# FDIF register map
Vendor: Texas Instruments
Peripheral module from a debugger description file (folder omap4460).
Registers are 32-bit, read-only, no defined reset value unless marked. A register's access mark holds for its fields unless they carry their own. Offsets are as the file gives them; lines under a group give offsets from that group; [hi:lo] are bit positions; {n}, {i} and the like mark numbered series; 'fields as' and 'values as' point back to an identical list; <NAME> marks a mode.

## FDIF
0x00 FDIF_REVISION — IP Revision Identifier (X.Y.R) Used by software to track features, bugs, and compatibility
  [31:0] REVISION — IP Revision number
0x04 FDIF_HWINFO reset 0xF — Information about the IP module's hardware configuration, that is, typically the module's HDL generics (if any). Actual field format and encoding is up to the module's designer to decide.
  [3:0] FDIF_TAGS — Hardware design value. This bit field reflects the value of the FDIF_TAG generic parameter. 0x0: 1 tag supported 0x1: 2 tags supported [...] 0xF: 16 tags supported
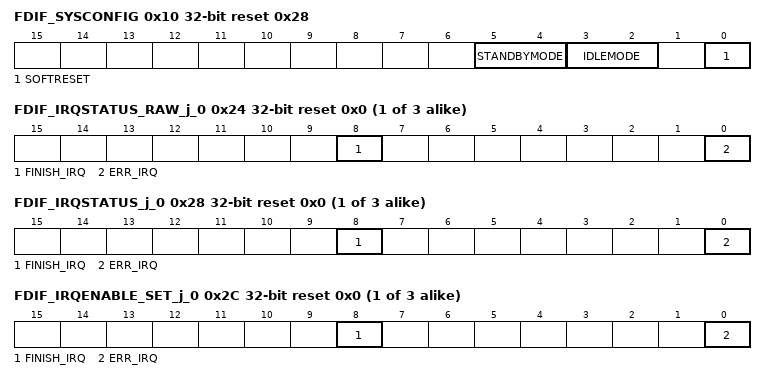
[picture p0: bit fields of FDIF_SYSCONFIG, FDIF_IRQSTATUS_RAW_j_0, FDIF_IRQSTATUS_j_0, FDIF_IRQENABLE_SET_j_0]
0x10 FDIF_SYSCONFIG access per field reset 0x28 — Clock management configuration
  [5:4] STANDBYMODE rw — Configuration of the local initiator state management mode. By definition, initiator may generate read/write transaction as long as it is out of STANDBY state.
    0=Force-standby mode: local initiator is unconditionally placed in standby state. Backup mode, for debug only.; 1=No-standby mode: local initiator is unconditionally placed out of standby state. Backup mode, for debug only.; 2=Smart-standby mode: local initiator standby status depends on local conditions, that is, the module's functional requirement from the initiator. IP module shall not generate (initiator-related) wake-up events.
  [3:2] IDLEMODE rw — Configuration of the local target state management mode. By definition, target can handle read/write transaction as long as it is out of IDLE state.
    0=Force-idle mode: local target's idle state follows (acknowledges) the system's idle requests unconditionally, that is, regardless of the IP module's internal requirements. Backup mode, for debug only.; 1=No-idle mode: local target never enters idle state. Backup mode, for debug only.; 2=Smart-idle mode: local target's idle state eventually follows (acknowledges) the system's idle requests, depending on the IP module's internal requirements. IP module shall not generate (IRQ- or DMA-request-related) wake-up events.
  [0] SOFTRESET rw — Software reset.
    0=SOFTRESET_0_r (Reset done, no pending action); 0=SOFTRESET_0_w (No action); 1=SOFTRESET_1_w (Initiate software reset); 1=SOFTRESET_1_r (Reset (software or other) ongoing)
{0x24+0x10*i} FDIF_IRQSTATUS_RAW_j_{i} access not given reset 0x0 (i=0..2) — Per-event raw interrupt status vector, line #n. Raw status is set even if event is not enabled. Write 1 to set the (raw) status, mostly for debug.
  [8] FINISH_IRQ — Face detection processing done. (access RW W1toSet)
    0=FINISH_IRQ_0_w (No action); 0=FINISH_IRQ_0_r (No event pending); 1=FINISH_IRQ_1_r (Event pending); 1=FINISH_IRQ_1_w (Set event (debug))
  [0] ERR_IRQ — Error received by the L3 port. (access RW W1toSet)
    0=ERR_IRQ_0_w (No action); 0=ERR_IRQ_0_r (No event pending); 1=ERR_IRQ_1_r (Event pending); 1=ERR_IRQ_1_w (Set event (debug))
{0x28+0x10*i} FDIF_IRQSTATUS_j_{i} access not given reset 0x0 (i=0..2) — Per-event 'enabled' interrupt status vector, line #n. Enabled status is not set unless event is enabled. Write 1 to clear the status after interrupt has been serviced (raw status gets cleared, that is, even if not enabled).
  [8] FINISH_IRQ — Face detection processing done. (access RW W1toClr)
    0=FINISH_IRQ_0_w (No action); 0=FINISH_IRQ_0_r (No (enabled) event pending); 1=FINISH_IRQ_1_r (Event pending); 1=FINISH_IRQ_1_w (Clear (raw) event)
  [0] ERR_IRQ — Error received by the L3 port. (access RW W1toClr)
    0=ERR_IRQ_0_w (No action); 0=ERR_IRQ_0_r (No (enabled) event pending); 1=ERR_IRQ_1_r (Event pending); 1=ERR_IRQ_1_w (Clear (raw) event)
{0x2C+0x10*i} FDIF_IRQENABLE_SET_j_{i} access not given reset 0x0 (i=0..2) — Per-event interrupt enable bit vector, line #n. Write 1 to set (enable interrupt). Readout equal to corresponding _CLR register.
  [8] FINISH_IRQ — Face detection processing done. (access RW W1toSet)
    0=FINISH_IRQ_0_w (No action); 0=FINISH_IRQ_0_r (Interrupt disabled (masked)); 1=FINISH_IRQ_1_r (Interrupt enabled); 1=FINISH_IRQ_1_w (Enable interrupt)
  [0] ERR_IRQ — Error received by the L3 port. (access RW W1toSet)
    0=ERR_IRQ_0_w (No action); 0=ERR_IRQ_0_r (Interrupt disabled (masked)); 1=ERR_IRQ_1_r (Interrupt enabled); 1=ERR_IRQ_1_w (Enable interrupt)
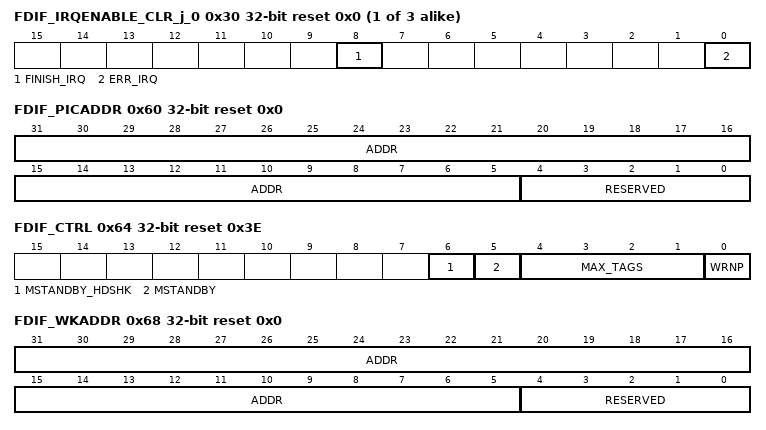
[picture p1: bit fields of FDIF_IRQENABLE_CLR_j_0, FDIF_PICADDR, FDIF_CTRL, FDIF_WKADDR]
{0x30+0x10*i} FDIF_IRQENABLE_CLR_j_{i} access not given reset 0x0 (i=0..2) — Per-event interrupt enable bit vector, line #n. Write 1 to clear (disable interrupt). Readout equal to corresponding _SET register.
  [8] FINISH_IRQ — Face detection processing done. (access RW W1toClr)
    0=FINISH_IRQ_0_w (No action); 0=FINISH_IRQ_0_r (Interrupt disabled (masked)); 1=FINISH_IRQ_1_r (Interrupt enabled); 1=FINISH_IRQ_1_w (Disable interrupt)
  [0] ERR_IRQ — Error received by the L3 port. (access RW W1toClr)
    0=ERR_IRQ_0_w (No action); 0=ERR_IRQ_0_r (Interrupt disabled (masked)); 1=ERR_IRQ_1_r (Interrupt enabled); 1=ERR_IRQ_1_w (Disable interrupt)
0x60 FDIF_PICADDR access per field reset 0x0 — Picture data store address
  [31:5] ADDR rw — Picture data store address. The 5 least significant bits are forced to 0.
  [4:0] RESERVED ro — Read returns 0.
0x64 FDIF_CTRL access per field reset 0x3E
  [6] MSTANDBY_HDSHK ro — MStandby / Wait power management handshaking status bit The power management framework of the FDIF module is based on the handshaking of the MSTANDBY and WAIT signals. When going from a idle to normal power management transition, the software polls for FDIF_CTRL.MSTANDBY_HDSHK = 1 before starting the face detection processing.
    0=MSTANDBY_HDSHK_0_r (Handshaking not completed. Do not initiate traffic on L3.); 1=MSTANDBY_HDSHK_1_r (Handshaking completed. Can safely use the FDIF module.)
  [5] MSTANDBY rw — MStandby signal generation. This bit shall be set to initiate a power management transition from NORMAL to IDLE or IDLE to NORMAL.
    0=Write: Clear MStandby signal. One polls.MSTANDBY_HDSHK = 1 after writing this bit to ensure that the power management handshaking is completed.; 1=Write: Asserts MStandby signal
  [4:1] MAX_TAGS rw — Max interconnect tags. This bit field sets the maximum number of interconnect tags that the module shall use. This number is programmable between 1 (MAX_TAGS = 0) and FDIF_TAGS (MAX_TAGS = FDIF_TAGS - 1). The value of MAX_TAGS is reflected in the FIDIF_HWINFO register setting. This register setting is expected to have impact on performance. It shall be set once at initialization. Higher value will give more bandwidth to the initiator. Lower value will give less bandwidth to the initiator. This value shall be set as low as possible such that other system initiators are not penalized.
  [0] WRNP rw — L3 port non-posted write control. Dynamic usage of this feature is not supported. This bit shall be set at initialization and not modified hereafter until the processing is completed. When non-posted writes are used, tags shall be used for best performance (MAX_TAGS &gt; 1).
    0=All writes are non posted; 1=All writes are posted
0x68 FDIF_WKADDR access per field reset 0x0
  [31:5] ADDR rw — Work area address The 5 least significant bits are forced to 0.
  [4:0] RESERVED ro — Read returns 0.
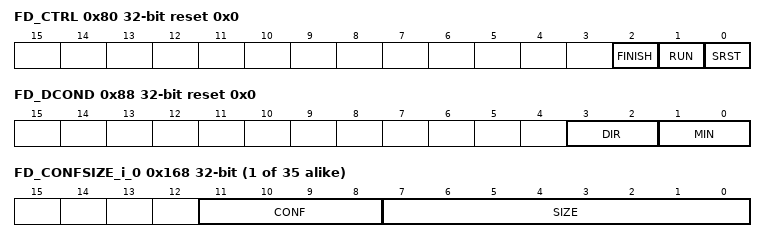
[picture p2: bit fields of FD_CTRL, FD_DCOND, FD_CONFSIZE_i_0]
0x80 FD_CTRL access per field reset 0x0 — Control register Don't set more than 2 bits to '1' at the same time. Otherwise, operations cannot be guaranteed.
  [2] FINISH rw — Process Completion Flag Clear
    0=Write: Disable Read: Process incomplete; 1=Write: Process complete flag clear Read: Process complete
  [1] RUN rw — Process Start Request
    0=Write: Disable Read: No processing; 1=Write: Process start request Read: Processing data
  [0] SRST rw — Software Reset This bit shall not be used to reset the FDIF module. Instead, the FDIF_SYSCONFIG[0] SOFTRESET bit shall be used for complete soft reset.
    0=Write: Disable Read: Reset cancel; 1=Write: Reset Read: Under reset
0x84 FD_DNUM reset 0x0 — Face Detection Result Count Register
  [5:0] DNUM — Face detection result count. Up to 35 faces can be detected. Number of face(s) detected: 0x0: 0 face detected 0x1: 1 face detected 0x2: 2 faces detected [...] 0x23: 35 faces detected 0x24 to 0x3F: unused
0x88 FD_DCOND access per field reset 0x0 — Detection Condition Setting Register
  [3:2] DIR rw — Detection direction setting
    0=Executes only for UP; 1=Executes only for RIGHT; 2=Executes only for LEFT
  [1:0] MIN rw — Reserved
    0=Set the min face size to 20 pixels; 1=Set the min face size to 25 pixels; 2=Set the min face size to 32 pixels; 3=Set the min face size to 40 pixels
0x8C FD_STARTX access per field reset 0x0 — Detection Area Setting Register: X Start Coordinate.
  [7:0] STARTX rw — Starting X coordinates Permitted values are 0&lt;=STARTX&lt;=160
0x90 FD_STARTY access per field reset 0x0 — Detection Area Setting Register: Y Start Coordinate.
  [6:0] STARTY rw — Starting Y coordinates Permitted values are 0&lt;=STARTY&lt;=120
0x94 FD_SIZEX access per field reset 0x140 — Detection Area Setting Register: X Direction Size
  [8:0] SIZEX rw — X Direction Size
0x98 FD_SIZEY access per field reset 0xF0 — Detection Area Setting Register: Y Direction Size
  [7:0] SIZEY rw — Y Direction Size
0x9C FD_LHIT access per field reset 0x5 — Threshold Setting Register
  [3:0] LHIT rw — Threshold Permitted values are 0x0 to 0x9
{0x160+0x10*i} FD_CENTERX_i_{i} (i=0..34) — Detection Result: X Coordinate. Its value is undefined after reset.
  [8:0] CENTERX — Face position: center X coordinate The coordinates given by (FD_CENTERX_i, FD_CENTERY_i) give the central coordinates of the face position. Permitted values are 0x0 to 0x13F
{0x164+0x10*i} FD_CENTERY_i_{i} (i=0..34) — Detection Result: Y Coordinate. Its value is undefined after reset.
  [7:0] CENTERY — Face position: center Y coordinate The coordinates given by (FD_CENTERX_i, FD_CENTERY_i) give the central coordinates of the face position. Permitted values are 0x0 to 0xEF
{0x168+0x10*i} FD_CONFSIZE_i_{i} (i=0..34) — Detection Result: Confidence Level and Size. Its value is undefined after reset.
  [11:8] CONF — Confidence level Permitted values are 0x0 (high) to 0x9 (low)
  [7:0] SIZE — Detection result face size Permitted values 0x14 to 0xF0
{0x16C+0x10*i} FD_ANGLE_i_{i} (i=0..34) — Detection Result: Angle. Its value is undefined after reset.
  [8:0] ANGLE — Detection result face angle Permitted values: When DIR = 0: 0x0 (0 deg) to 0x1E (30 deg) and 0x14A (330 deg) to 0x167 (359 deg) When DIR = 1: 0x03C (60 deg) to 0x078 (120 deg) When DIR = 2: 0x0F0 (240 deg) to 0x12C (300 deg)
